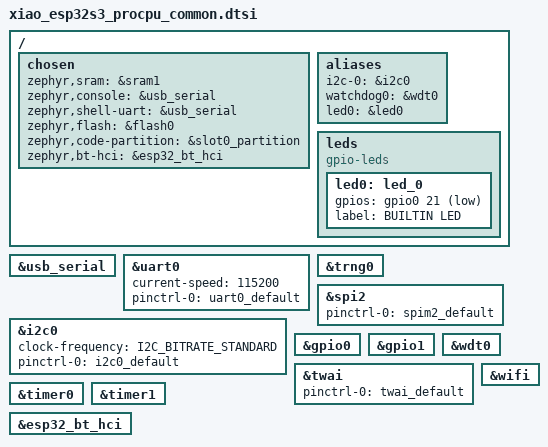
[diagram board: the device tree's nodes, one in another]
/*
 * Copyright (c) 2023 Seeed Studio inc.
 *
 * SPDX-License-Identifier: Apache-2.0
 */

/dts-v1/;

#include <espressif/esp32s3/esp32s3_wroom_n8r8.dtsi>
#include "xiao_esp32s3-pinctrl.dtsi"
#include "seeed_xiao_connector.dtsi"

/ {
	chosen {
		zephyr,sram = &sram1;
		zephyr,console = &usb_serial;
		zephyr,shell-uart = &usb_serial;
		zephyr,flash = &flash0;
		zephyr,code-partition = &slot0_partition;
		zephyr,bt-hci = &esp32_bt_hci;
	};

	aliases {
		i2c-0 = &i2c0;
		watchdog0 = &wdt0;
		led0 = &led0;
	};

	leds {
		compatible = "gpio-leds";
		led0: led_0 {
			gpios = <&gpio0 21 GPIO_ACTIVE_LOW>;
			label = "BUILTIN LED";
		};
	};

};

&usb_serial {
	status = "okay";
};

&uart0 {
	status = "okay";
	current-speed = <115200>;
	pinctrl-0 = <&uart0_default>;
	pinctrl-names = "default";
};

&i2c0 {
	status = "okay";
	clock-frequency = <I2C_BITRATE_STANDARD>;
	pinctrl-0 = <&i2c0_default>;
	pinctrl-names = "default";
};

&trng0 {
	status = "okay";
};

&spi2 {
	#address-cells = <1>;
	#size-cells = <0>;
	status = "okay";
	pinctrl-0 = <&spim2_default>;
	pinctrl-names = "default";
};

&gpio0 {
	status = "okay";
};

&gpio1 {
	status = "okay";
};

&wdt0 {
	status = "okay";
};

&twai {
	pinctrl-0 = <&twai_default>;
	pinctrl-names = "default";
};

&timer0 {
	status = "okay";
};

&timer1 {
	status = "okay";
};

&esp32_bt_hci {
	status = "okay";
};

&wifi {
	status = "okay";
};
